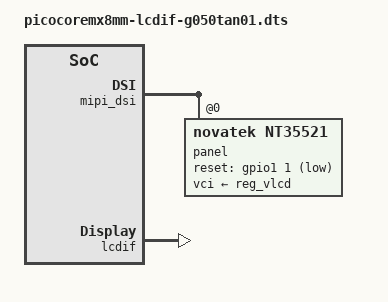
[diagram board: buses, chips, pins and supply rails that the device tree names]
/*
* Copyright (C) 2019 F&S Elektronik Systeme GmbH
*
* This program is free software; you can redistribute it and/or modify
* it under the terms of the GNU General Public License version 2 as
* published by the Free Software Foundation.
*/

#include "picocoremx8mm.dts"


&mipi_dsi {
	status = "okay";

	panel@0 {
		status = "okay";
                compatible = "novatek,nt35521";
		reg = <0>;
		pinctrl-0 = <&pinctrl_mipi_dsi_en>;
		reset-gpio = <&gpio1 1 GPIO_ACTIVE_LOW>;
		vci-supply = <&reg_vlcd>;
		dsi-lanes = <4>;
		/* Video mode
		 * 0: burst mode
		 * 1: non-burst mode with sync event
		 * 2: non-burst mode with sync pulse
		 */
		video-mode = <0>;
		panel-width-mm = <62>;
		panel-height-mm = <110>;

		display-timings {
			timing {
				clock-frequency = <77940000>;
				hactive = <720>;
				vactive = <1280>;
				hback-porch = <72>;
				hfront-porch = <56>;
				vback-porch = <38>;
				vfront-porch = <3>;
				hsync-len = <128>;
				vsync-len = <10>;
				hsync-active = <0>;
				vsync-active = <0>;
				de-active = <0>;
				pixelclk-active = <0>;
			};
		};
	};
};

&lcdif {
	status = "okay";
};

